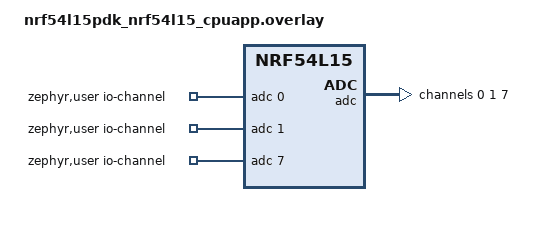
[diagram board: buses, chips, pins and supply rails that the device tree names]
/*
 * SPDX-License-Identifier: Apache-2.0
 *
 * Copyright (c) 2024 Nordic Semiconductor ASA
 */

/ {
	zephyr,user {
		io-channels = <&adc 0>, <&adc 1>, <&adc 7>;
	};
};

/ {
	aliases {
		adc0 = &adc;
	};
};

&adc {
	#address-cells = <1>;
	#size-cells = <0>;

	channel@0 {
		reg = <0>;
		zephyr,gain = "ADC_GAIN_1";
		zephyr,reference = "ADC_REF_INTERNAL";
		zephyr,acquisition-time = <ADC_ACQ_TIME_DEFAULT>;
		zephyr,input-positive = <NRF_SAADC_AIN4>; /* P1.11 */
		zephyr,resolution = <10>;
	};

	channel@1 {
		reg = <1>;
		zephyr,gain = "ADC_GAIN_1";
		zephyr,reference = "ADC_REF_INTERNAL";
		zephyr,acquisition-time = <ADC_ACQ_TIME_DEFAULT>;
		zephyr,input-positive = <NRF_SAADC_AIN2>; /* P1.06 */
		zephyr,resolution = <12>;
		zephyr,oversampling = <8>;
	};

	channel@7 {
		reg = <7>;
		zephyr,gain = "ADC_GAIN_1";
		zephyr,reference = "ADC_REF_INTERNAL";
		zephyr,acquisition-time = <ADC_ACQ_TIME_DEFAULT>;
		zephyr,input-positive = <NRF_SAADC_AIN6>; /* P1.13 */
		zephyr,input-negative = <NRF_SAADC_AIN7>; /* P1.14 */
		zephyr,resolution = <12>;
	};
};
